# a34g43x register map
Vendor: ABOV Semiconductor Co., Ltd.; File version: 1.0
CPU: CM4 r0p1, little endian, MPU, FPU, VTOR, 4 interrupt priority bits
Registers are 32-bit, read-write, reset 0x0 unless marked. A register's access mark holds for its fields unless they carry their own. Offsets are from the block's base; [hi:lo] are bit positions; {n}, {i} and the like mark numbered series.

## CFMC — CODE FLASH MEMORY CONTROLLER
Base 0x41000000
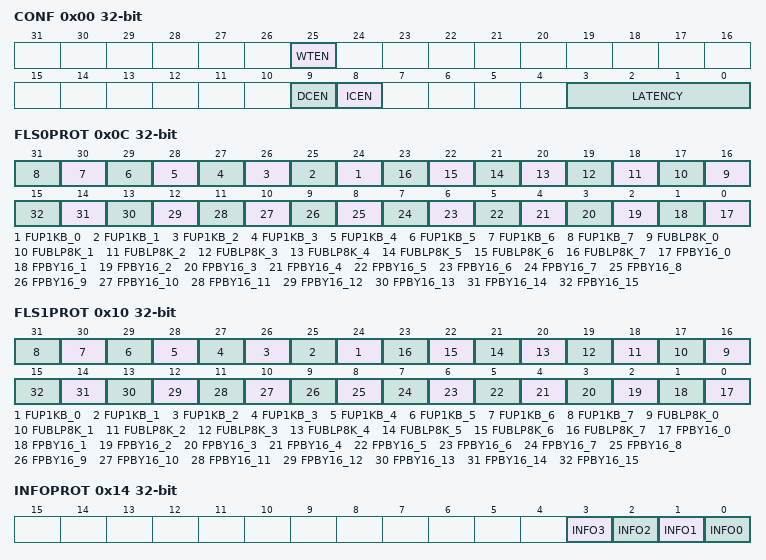
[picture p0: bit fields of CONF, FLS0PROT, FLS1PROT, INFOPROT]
0x00 CONF — Code Flash Memory Config Register
  [25] WTEN — Whether to Enable or Disable Code FLASH Write
    0=Disable write; 1=Enable write
  [9] DCEN — Whether to Enable or Disable Data Cache
    0=Disable data cache; 1=Enable data cache
  [8] ICEN — Whether to Enable or Disable Instruction Cache
    0=Disable instruction cache; 1=Enable instruction cache
  [3:0] LATENCY — Flash Wait Value Bits
0x04 FLSKEY wo — Code Flash Memory Access Key Register
  [31:0] FKEY — Flash Memory Access Key, KEY1(0x01234567) -> KEY2(0x12345678) -> KEY3(0x23456789)
0x08 INFOKEY wo — Code Flash INFO Access Key Register
  [31:0] INFOKEY — INFO Access Key Bits, KEY1(0x3456789A) -> KEY2(0x456789AB) -> KEY3(0x56789ABC)
0x0C FLS0PROT — Code Flash 0 Protection Register
  [n+24] FUP1KB_{n} (n=0..7) — Flash upper 1KB Unprotection (Total : 8 KB)
  [n+16] FUBLP8K_{n} (n=0..7) — User Boot Loader 8KB Protection (Total : 64 KB)
  [n] FPBY16_{n} (n=0..15) — Code Flash Area Protection (Code Flash Size 2 MB : 64 KB / Code Flash Size 1 MB : 32 KB)
0x10 FLS1PROT — Code Flash 1 Protection Register
  [n+24] FUP1KB_{n} (n=0..7) — Flash upper 8KB Unprotection
  [n+16] FUBLP8K_{n} (n=0..7) — User Boot Loader 64KB Protection
  [n] FPBY16_{n} (n=0..15) — Code Flash Area Protection (Code Flash Size 2 MB : 64 KB / Code Flash Size 1 MB : 32 KB)
0x14 INFOPROT — Code Flash INFO Protection Register
  [3] INFO3 — INFO3 Area Protection bit, 0x0F00_0C00 0x0F00_0FFF
  [2] INFO2 — INFO2 Area Protection bit, 0x0F00_0800 0x0F00_0BFF
  [1] INFO1 — INFO1 Area Protection bit, 0x0F00_0400 0x0F00_07FF
  [0] INFO0 — INFO0 Area Protection bit, 0x0F00_0000 0x0F00_03FF
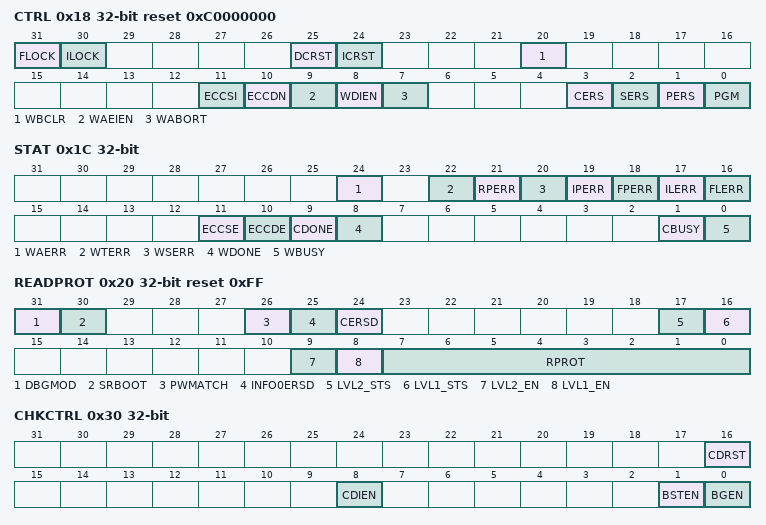
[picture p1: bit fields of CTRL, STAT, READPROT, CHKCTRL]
0x18 CTRL reset 0xC0000000 — Code Flash Access Control Register
  [31] FLOCK — Flash Memory Lock Bit
  [30] ILOCK — INFO memory Lock Bit
  [25] DCRST — Data Cache Reset Control bit (Automatically cleared)
  [24] ICRST — Instruction Cache Reset Control Bit (Automatically cleared)
  [20] WBCLR — Write buffer clear enable bit
  [11] ECCSI — Whether to Enable or Disable ECC Single Error Interrupt
    0=Disable interrupt; 1=Enable interrupt
  [10] ECCDN — Whether to Enable or Disable ECC Double Error Non-Maskable Interrupt
    0=Disable interrupt; 1=Enable interrupt
  [9] WAEIEN wo — Write address error enable bit
    0=Disable interrupt; 1=Enable interrupt
  [8] WDIEN — Write done interrupt enable bit
    0=Disable interrupt; 1=Enable interrupt
  [7] WABORT — Abort Write Operation bit
    0=Disable (No Effect); 1=Enable (Abort write operation)
  [3] CERS — Bulk(Chip) Erase Mode Bit
    0=Disable bulk erase; 1=Enable bulk erase
  [2] SERS — Sector(4KB) Erase Mode
    0=Disable sector erase; 1=Enable sector erase
  [1] PERS — Page(1KB) Erase Mode
    0=Disable page erase; 1=Enable page erase
  [0] PGM — Program Mode
    0=Disable program; 1=Enable program
0x1C STAT — Code Flash Access Status Register
  [24] WAERR — Write Address Error (cleared by writing a '1')
  [22] WTERR — Write Timeout Error (cleared by writing a '1')
  [21] RPERR — Read Protect Error (cleared by writing a '1')
  [20] WSERR — Write Sequence Error (cleared by writing a '1')
  [19] IPERR — INFO Protect Error (cleared by writing a '1')
  [18] FPERR — Flash Protect Error (cleared by writing a '1')
  [17] ILERR — INFO Lock Error (cleared by writing a '1')
  [16] FLERR — Flash Lock Error (cleared by writing a '1')
  [11] ECCSE — ECC Single Error (cleared by writing a '1')
  [10] ECCDE — ECC Double Error (cleared by writing a '1')
  [9] CDONE — Checksum Done Check (cleared by writing a '1')
  [8] WDONE — Write Done Check (cleared by writing a '1')
  [1] CBUSY ro — Checksum Busy Check
    0=Not_Busy (Checksum Not Busy); 1=Busy (Checksum Busy)
  [0] WBUSY ro — Write Busy Check
    0=Not_Busy (Write Not Busy); 1=Busy (Write Busy)
0x20 READPROT reset 0xFF — Code Flash Read Protection Register
  [31] DBGMOD ro — Debug Operating Status Bit
  [30] SRBOOT ro — Sram Boot Mode Status Bit
  [26] PWMATCH ro — Password Match Flag Bit
  [25] INFO0ERSD ro — Chip & INFO0 Erase Done Flag Bit
  [24] CERSD ro — Bulk Erase Done Flag Bit
  [17] LVL2_STS ro — Protection Level 2 Status Bit (Raw Data)
  [16] LVL1_STS ro — Protection Level 1 Status Bit (Raw Data)
  [9] LVL2_EN ro — Protection Level 2 Enable Bit
  [8] LVL1_EN ro — Protection Level 1 Enable Bit
  [7:0] RPROT — Read Protection Control Bit
0x24 PWIN wo — Code Flash Read Protection Password Input Register
  [31:0] PWIN — Password Input Data Bit
0x30 CHKCTRL — Code Flash Checksum Control Register
  [16] CDRST wo — Checksum Data Reset (Auto Cleared)
    0=No_Effect; 1=Reset
  [8] CDIEN — Checksum Done Interrupt
    0=Disable interrupt; 1=Enable interrupt
  [1] BSTEN wo — Burst Mode
    0=Disable burst mode; 1=Enable burst mode
  [0] BGEN wo — Back Ground Mode
    0=Disable back ground mode; 1=Enable back ground mode
0x34 CHKDOUT ro reset 0xFFFF — Code Flash Checksum Data Output Register
  [15:0] CDOUT — Flash Checksum Data Output bit
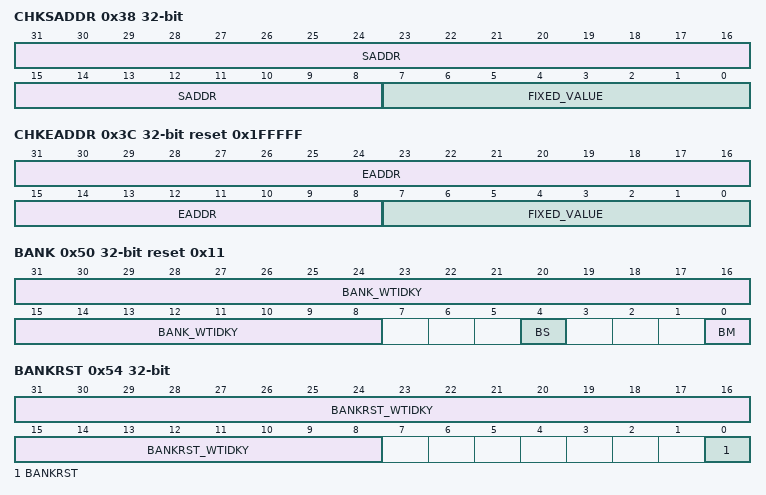
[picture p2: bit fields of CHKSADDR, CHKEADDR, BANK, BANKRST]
0x38 CHKSADDR — Code Flash Checksum Start Address Resgister
  [31:8] SADDR — Flash Checksum Start Address bit
  [7:0] FIXED_VALUE ro — Fixed Vaule
0x3C CHKEADDR reset 0x1FFFFF — Code Flash Checksum End Address Register
  [31:8] EADDR — Flash Checksum End Address bit
  [7:0] FIXED_VALUE ro
0x40 WTIMEOUT — Code Flash Write Timeout Register
  [31:0] WTIMEOUT — Write timeout count
0x50 BANK reset 0x11 — Code Flash Bank Control Register
  [31:8] BANK_WTIDKY wo — Bank register Identification Key, key is 0x5A3C0F
  [4] BS — Bank Swap (Vdlid in bank mode)
    0=Swap mode; 1=No swap mode
  [0] BM — Bank Mode
    0=Bank mode; 1=Linear mode
0x54 BANKRST — Code Flash Bank Reset Register
  [31:8] BANKRST_WTIDKY wo — Bank Reset register Identification Key, key is 0x5A3C0F
  [0] BANKRST wo — Reset for bank swap
    0=Disable (No Effect); 1=Enable (Reset)
0x60 ECCEADDR ro — Code Flash ECC Error Address Register
  [31:0] ECCEA — Code Flash ECC Error Address bit
{0x64+4i} ECCEDATA{i} ro (i=0..3) — Code Flash ECC Error Data{i} Register
  [31:0] ECCED{i} — Code Flash ECC Error Data{i} bit
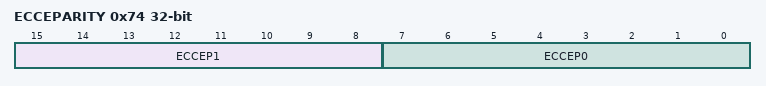
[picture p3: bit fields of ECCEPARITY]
0x74 ECCEPARITY ro — Code Flash ECC Error Parity Register
  [15:8] ECCEP1 — Code Flash ECC Error Parity1
  [7:0] ECCEP0 — Code Flash ECC Error Parity0
0xF30 PWPRST wo — Code Flash Read Protection Password Preset Register
  [31:0] PWPRST — Password Preset Data Bit
